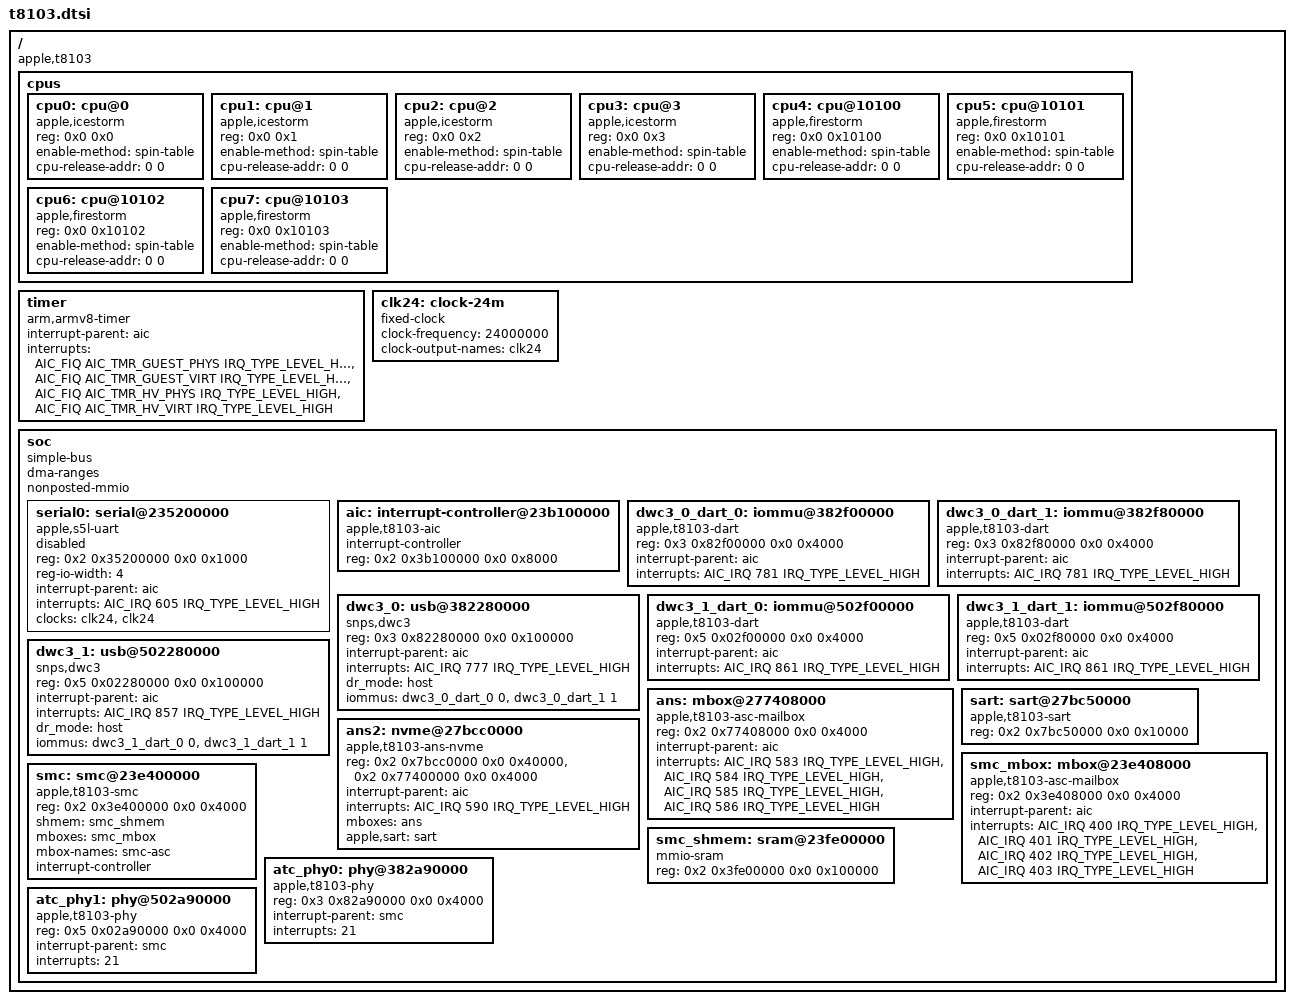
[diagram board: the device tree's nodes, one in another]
// SPDX-License-Identifier: GPL-2.0+ OR MIT
/*
 * Apple T8103 "M1" SoC
 *
 * Other names: H13G, "Tonga"
 *
 * Copyright The Asahi Linux Contributors
 */

#include <dt-bindings/interrupt-controller/apple-aic.h>
#include <dt-bindings/interrupt-controller/irq.h>

/ {
	compatible = "apple,t8103", "apple,arm-platform";

	#address-cells = <2>;
	#size-cells = <2>;

	cpus {
		#address-cells = <2>;
		#size-cells = <0>;

		cpu0: cpu@0 {
			compatible = "apple,icestorm";
			device_type = "cpu";
			reg = <0x0 0x0>;
			enable-method = "spin-table";
			cpu-release-addr = <0 0>; /* To be filled by loader */
		};

		cpu1: cpu@1 {
			compatible = "apple,icestorm";
			device_type = "cpu";
			reg = <0x0 0x1>;
			enable-method = "spin-table";
			cpu-release-addr = <0 0>; /* To be filled by loader */
		};

		cpu2: cpu@2 {
			compatible = "apple,icestorm";
			device_type = "cpu";
			reg = <0x0 0x2>;
			enable-method = "spin-table";
			cpu-release-addr = <0 0>; /* To be filled by loader */
		};

		cpu3: cpu@3 {
			compatible = "apple,icestorm";
			device_type = "cpu";
			reg = <0x0 0x3>;
			enable-method = "spin-table";
			cpu-release-addr = <0 0>; /* To be filled by loader */
		};

		cpu4: cpu@10100 {
			compatible = "apple,firestorm";
			device_type = "cpu";
			reg = <0x0 0x10100>;
			enable-method = "spin-table";
			cpu-release-addr = <0 0>; /* To be filled by loader */
		};

		cpu5: cpu@10101 {
			compatible = "apple,firestorm";
			device_type = "cpu";
			reg = <0x0 0x10101>;
			enable-method = "spin-table";
			cpu-release-addr = <0 0>; /* To be filled by loader */
		};

		cpu6: cpu@10102 {
			compatible = "apple,firestorm";
			device_type = "cpu";
			reg = <0x0 0x10102>;
			enable-method = "spin-table";
			cpu-release-addr = <0 0>; /* To be filled by loader */
		};

		cpu7: cpu@10103 {
			compatible = "apple,firestorm";
			device_type = "cpu";
			reg = <0x0 0x10103>;
			enable-method = "spin-table";
			cpu-release-addr = <0 0>; /* To be filled by loader */
		};
	};

	timer {
		compatible = "arm,armv8-timer";
		interrupt-parent = <&aic>;
		interrupt-names = "phys", "virt", "hyp-phys", "hyp-virt";
		interrupts = <AIC_FIQ AIC_TMR_GUEST_PHYS IRQ_TYPE_LEVEL_HIGH>,
			     <AIC_FIQ AIC_TMR_GUEST_VIRT IRQ_TYPE_LEVEL_HIGH>,
			     <AIC_FIQ AIC_TMR_HV_PHYS IRQ_TYPE_LEVEL_HIGH>,
			     <AIC_FIQ AIC_TMR_HV_VIRT IRQ_TYPE_LEVEL_HIGH>;
	};

	clk24: clock-24m {
		compatible = "fixed-clock";
		#clock-cells = <0>;
		clock-frequency = <24000000>;
		clock-output-names = "clk24";
	};

	soc {
		compatible = "simple-bus";
		#address-cells = <2>;
		#size-cells = <2>;

		ranges;
		dma-ranges;
		nonposted-mmio;

		serial0: serial@235200000 {
			compatible = "apple,s5l-uart";
			reg = <0x2 0x35200000 0x0 0x1000>;
			reg-io-width = <4>;
			interrupt-parent = <&aic>;
			interrupts = <AIC_IRQ 605 IRQ_TYPE_LEVEL_HIGH>;
			/*
			 * TODO: figure out the clocking properly, there may
			 * be a third selectable clock.
			 */
			clocks = <&clk24>, <&clk24>;
			clock-names = "uart", "clk_uart_baud0";
			status = "disabled";
		};

		aic: interrupt-controller@23b100000 {
			compatible = "apple,t8103-aic", "apple,aic";
			#interrupt-cells = <3>;
			interrupt-controller;
			reg = <0x2 0x3b100000 0x0 0x8000>;
		};

		dwc3_0_dart_0: iommu@382f00000 {
			compatible = "apple,t8103-dart";
			reg = <0x3 0x82f00000 0x0 0x4000>;
			interrupt-parent = <&aic>;
			interrupts = <AIC_IRQ 781 IRQ_TYPE_LEVEL_HIGH>;
			#iommu-cells = <1>;
		};

		dwc3_0_dart_1: iommu@382f80000 {
			compatible = "apple,t8103-dart";
			reg = <0x3 0x82f80000 0x0 0x4000>;
			interrupt-parent = <&aic>;
			interrupts = <AIC_IRQ 781 IRQ_TYPE_LEVEL_HIGH>;
			#iommu-cells = <1>;
		};

		dwc3_0: usb@382280000{
			compatible = "snps,dwc3";
			reg = <0x3 0x82280000 0x0 0x100000>;
			interrupt-parent = <&aic>;
			interrupts = <AIC_IRQ 777 IRQ_TYPE_LEVEL_HIGH>;
			dr_mode = "host";
			iommus = <&dwc3_0_dart_0 0>, <&dwc3_0_dart_1 1>;
		};

		dwc3_1_dart_0: iommu@502f00000 {
			compatible = "apple,t8103-dart";
			reg = <0x5 0x02f00000 0x0 0x4000>;
			interrupt-parent = <&aic>;
			interrupts = <AIC_IRQ 861 IRQ_TYPE_LEVEL_HIGH>;
			#iommu-cells = <1>;
		};

		dwc3_1_dart_1: iommu@502f80000 {
			compatible = "apple,t8103-dart";
			reg = <0x5 0x02f80000 0x0 0x4000>;
			interrupt-parent = <&aic>;
			interrupts = <AIC_IRQ 861 IRQ_TYPE_LEVEL_HIGH>;
			#iommu-cells = <1>;
		};

		dwc3_1: usb@502280000{
			compatible = "snps,dwc3";
			reg = <0x5 0x02280000 0x0 0x100000>;
			interrupt-parent = <&aic>;
			interrupts = <AIC_IRQ 857 IRQ_TYPE_LEVEL_HIGH>;
			dr_mode = "host";
			iommus = <&dwc3_1_dart_0 0>, <&dwc3_1_dart_1 1>;
		};
		ans: mbox@277408000 {
			compatible = "apple,t8103-asc-mailbox";
			reg = <0x2 0x77408000 0x0 0x4000>;
			interrupt-parent = <&aic>;
			interrupts = <AIC_IRQ 583 IRQ_TYPE_LEVEL_HIGH>,
				<AIC_IRQ 584 IRQ_TYPE_LEVEL_HIGH>,
				<AIC_IRQ 585 IRQ_TYPE_LEVEL_HIGH>,
				<AIC_IRQ 586 IRQ_TYPE_LEVEL_HIGH>;
			interrupt-names = "send-empty", "send-not-empty",
				"recv-empty", "recv-not-empty";
			#mbox-cells = <0>;
		};

		sart: sart@27bc50000 {
			compatible = "apple,t8103-sart";
			reg = <0x2 0x7bc50000 0x0 0x10000>;
		};

		ans2: nvme@27bcc0000 {
			compatible = "apple,t8103-ans-nvme";
			reg = <0x2 0x7bcc0000 0x0 0x40000>, <0x2 0x77400000 0x0 0x4000>;
			reg-names = "nvme", "coproc";
			interrupt-parent = <&aic>;
			interrupts = <AIC_IRQ 590 IRQ_TYPE_LEVEL_HIGH>;
			mboxes = <&ans>;
			apple,sart = <&sart>;
		 };

		smc_mbox: mbox@23e408000 {
			compatible = "apple,t8103-asc-mailbox";
			reg = <0x2 0x3e408000 0x0 0x4000>;
			interrupt-parent = <&aic>;
			interrupts = <AIC_IRQ 400 IRQ_TYPE_LEVEL_HIGH>,
				<AIC_IRQ 401 IRQ_TYPE_LEVEL_HIGH>,
				<AIC_IRQ 402 IRQ_TYPE_LEVEL_HIGH>,
				<AIC_IRQ 403 IRQ_TYPE_LEVEL_HIGH>;
			interrupt-names = "send-empty", "send-not-empty",
				"recv-empty", "recv-not-empty";
			#mbox-cells = <0>;
		};

		smc: smc@23e400000 {
			compatible = "apple,t8103-smc";
			reg = <0x2 0x3e400000 0x0 0x4000>;
			shmem = <&smc_shmem>;
			mboxes = <&smc_mbox>;
			mbox-names = "smc-asc";
			interrupt-controller;
			#interrupt-cells = <1>;
		};

		smc_shmem: sram@23fe00000 {
			compatible = "mmio-sram";
			reg = <0x2 0x3fe00000 0x0 0x100000>;
		};

		atc_phy0: phy@382a90000 {
			compatible = "apple,t8103-phy";
			reg = <0x3 0x82a90000 0x0 0x4000>;
			reg-names = "usb-phy";
			interrupt-parent = <&smc>;
			interrupts = <21>;
		};

		atc_phy1: phy@502a90000 {
			compatible = "apple,t8103-phy";
			reg = <0x5 0x02a90000 0x0 0x4000>;
			reg-names = "usb-phy";
			interrupt-parent = <&smc>;
			interrupts = <21>;
		};
	};
};
